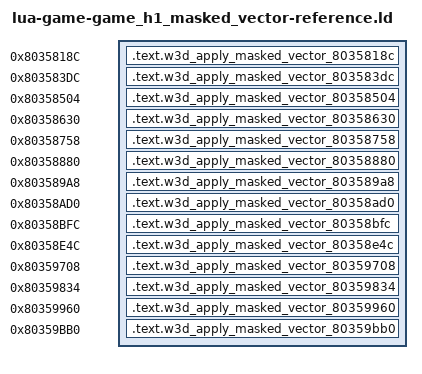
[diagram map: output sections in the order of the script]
/* Generated reference-only placements. All bodies are source-built. */
OUTPUT_FORMAT("elf32-powerpc")
OUTPUT_ARCH(powerpc)
ENTRY(w3d_apply_masked_vector_8035818c)
_SDA_BASE_ = 0x804b2540;
_SDA2_BASE_ = 0x804c2540;
SECTIONS {
  .text.w3d_apply_masked_vector_8035818c 0x8035818c : { *(.text.w3d_apply_masked_vector_8035818c) }
  .text.w3d_apply_masked_vector_803583dc 0x803583dc : { *(.text.w3d_apply_masked_vector_803583dc) }
  .text.w3d_apply_masked_vector_80358504 0x80358504 : { *(.text.w3d_apply_masked_vector_80358504) }
  .text.w3d_apply_masked_vector_80358630 0x80358630 : { *(.text.w3d_apply_masked_vector_80358630) }
  .text.w3d_apply_masked_vector_80358758 0x80358758 : { *(.text.w3d_apply_masked_vector_80358758) }
  .text.w3d_apply_masked_vector_80358880 0x80358880 : { *(.text.w3d_apply_masked_vector_80358880) }
  .text.w3d_apply_masked_vector_803589a8 0x803589a8 : { *(.text.w3d_apply_masked_vector_803589a8) }
  .text.w3d_apply_masked_vector_80358ad0 0x80358ad0 : { *(.text.w3d_apply_masked_vector_80358ad0) }
  .text.w3d_apply_masked_vector_80358bfc 0x80358bfc : { *(.text.w3d_apply_masked_vector_80358bfc) }
  .text.w3d_apply_masked_vector_80358e4c 0x80358e4c : { *(.text.w3d_apply_masked_vector_80358e4c) }
  .text.w3d_apply_masked_vector_80359708 0x80359708 : { *(.text.w3d_apply_masked_vector_80359708) }
  .text.w3d_apply_masked_vector_80359834 0x80359834 : { *(.text.w3d_apply_masked_vector_80359834) }
  .text.w3d_apply_masked_vector_80359960 0x80359960 : { *(.text.w3d_apply_masked_vector_80359960) }
  .text.w3d_apply_masked_vector_80359bb0 0x80359bb0 : { *(.text.w3d_apply_masked_vector_80359bb0) }
  /DISCARD/ : { *(.text*) *(.rodata*) *(.data*) *(.bss*) *(.sdata*) *(.sbss*) *(.comment) }
}
